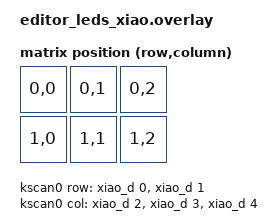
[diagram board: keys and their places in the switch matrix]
/* Generated by ZMK Editor from editor_leds_xiao.editor.json. */

#include <dt-bindings/zmk/matrix_transform.h>
#include <physical_layouts.dtsi>
#include <dt-bindings/led/led.h>

/ {
    chosen {
        zmk,kscan = &kscan0;
        zmk,physical-layout = &editor_leds_xiao_layout;
    };

    kscan0: kscan {
        compatible = "zmk,kscan-gpio-matrix";
        wakeup-source;
        diode-direction = "col2row";

        row-gpios
            = <&xiao_d  0 (GPIO_ACTIVE_HIGH | GPIO_PULL_DOWN)>
            , <&xiao_d  1 (GPIO_ACTIVE_HIGH | GPIO_PULL_DOWN)>
            ;

        col-gpios
            = <&xiao_d  2 GPIO_ACTIVE_HIGH>
            , <&xiao_d  3 GPIO_ACTIVE_HIGH>
            , <&xiao_d  4 GPIO_ACTIVE_HIGH>
            ;
    };

    default_transform: keymap_transform_0 {
        compatible = "zmk,matrix-transform";
        rows = <2>;
        columns = <3>;
        map = <
RC(0,0) RC(0,1) RC(0,2)
RC(1,0) RC(1,1) RC(1,2)
        >;
    };

    editor_leds_xiao_layout: editor_leds_xiao_layout {
        compatible = "zmk,physical-layout";
        display-name = "LED XIAO";
        transform = <&default_transform>;

        keys  //                     w   h    x    y     rot   rx   ry
            = <&key_physical_attrs 100 100    0    0      0    0    0>
            , <&key_physical_attrs 100 100  100    0      0    0    0>
            , <&key_physical_attrs 100 100  200    0      0    0    0>
            , <&key_physical_attrs 100 100    0  100      0    0    0>
            , <&key_physical_attrs 100 100  100  100      0    0    0>
            , <&key_physical_attrs 100 100  200  100      0    0    0>
            ;
    };
};

/ {
    chosen {
        zmk,underglow = &led_strip;
    };
};

&pinctrl {
    led_spi_default: led_spi_default {
        group1 {
            psels = <NRF_PSEL(SPIM_MOSI, 1, 15)>;
        };
    };
    led_spi_sleep: led_spi_sleep {
        group1 {
            psels = <NRF_PSEL(SPIM_MOSI, 1, 15)>;
            low-power-enable;
        };
    };
};

&spi3 {
    status = "okay";
    compatible = "nordic,nrf-spim";
    pinctrl-0 = <&led_spi_default>;
    pinctrl-1 = <&led_spi_sleep>;
    pinctrl-names = "default", "sleep";

    led_strip: ws2812@0 {
        compatible = "worldsemi,ws2812-spi";
        reg = <0>;
        spi-max-frequency = <4000000>;
        chain-length = <8>;
        spi-one-frame = <0x70>;
        spi-zero-frame = <0x40>;
        color-mapping = <LED_COLOR_ID_GREEN LED_COLOR_ID_RED LED_COLOR_ID_BLUE>;
    };
};

/* ZMK's external power switches the LEDs' power. */
/ {
    EXT_POWER {
        compatible = "zmk,ext-power-generic";
        control-gpios = <&xiao_d 9 GPIO_ACTIVE_HIGH>;
    };
};
